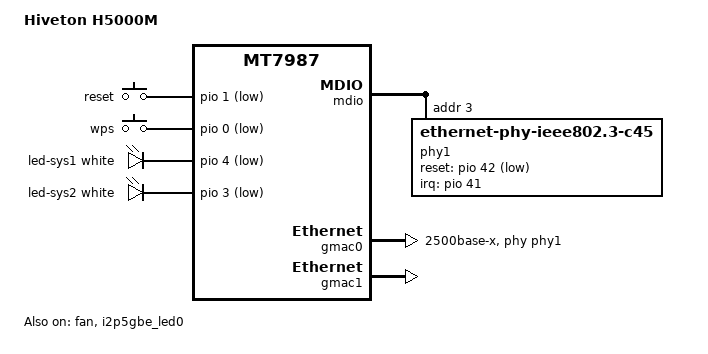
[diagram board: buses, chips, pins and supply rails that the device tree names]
// SPDX-License-Identifier: (GPL-2.0 OR MIT)
/*
 * Copyright (C) 2025 MediaTek Inc.
 * Author: Sam.Shih <sam.shih@mediatek.com>
 */

/dts-v1/;
#include "mt7987a.dtsi"
#include <dt-bindings/input/input.h>
#include "mt7987-emmc.dtsi"

/* MT7987A RFB DTS for DT overlay-based device tree */
/ {
	model = "Hiveton H5000M";
	compatible = "hiveton,h5000m", "mediatek,mt7987";

	chosen {
		bootargs = "console=ttyS0,115200n1 loglevel=8  \
                            earlycon=uart8250,mmio32,0x11000000 \
                            pci=pcie_bus_perf \
			    root=PARTLABEL=rootfs rootwait \
			    rootfstype=squashfs,f2fs";
	};

	gpio-keys {
		compatible = "gpio-keys";

		reset {
			label = "reset";
			linux,code = <KEY_RESTART>;
			gpios = <&pio 1 GPIO_ACTIVE_LOW>;
			debounce-interval = <10>;
		};

		wps {
			label = "wps";
			linux,code = <KEY_WPS_BUTTON>;
			gpios = <&pio 0 GPIO_ACTIVE_LOW>;
			debounce-interval = <10>;
		};
	};

	leds {
		compatible = "gpio-leds";

		led-sys1 {
			gpios = <&pio 4 GPIO_ACTIVE_LOW>;
			color = <LED_COLOR_ID_WHITE>;
			function = LED_FUNCTION_WLAN;
			function-enumerator = <1>;
		};

		led-sys2 {
			gpios = <&pio 3 GPIO_ACTIVE_LOW>;
			color = <LED_COLOR_ID_WHITE>;
			function = LED_FUNCTION_WLAN;
			function-enumerator = <0>;
		};
	};
};

&pcie0 {
	wifi-reset-gpios = <&pio 38 GPIO_ACTIVE_HIGH>;
	wifi-reset-msleep = <1000>;
};

&fan {
	pinctrl-names = "default";
	pinctrl-0 = <&pwm_fan_pins>;
	compatible = "pwm-fan";
	#cooling-cells = <2>;
	cooling-levels = <0 10 20 30 40 50 60 70 80 90 100 110 120 130 140 150 160 170 180 190 200 210 220 240 255>;
	pwms = <&pwm 1 50000 0>;
	status = "okay";
};

&mdio {
	phy1: phy@1 {
		compatible = "ethernet-phy-ieee802.3-c45";
		reg = <3>;
		reset-assert-us = <100000>;
		reset-deassert-us = <100000>;
		reset-gpios = <&pio 42 GPIO_ACTIVE_LOW>;
		interrupts = <41 IRQ_TYPE_LEVEL_LOW>;
		interrupt-parent = <&pio>;
		realtek,aldps-enable;
	};
};

&gmac0 {
	phy-mode = "2500base-x";
	phy-handle = <&phy1>;
	status = "okay";
};

&gmac1 {
	status = "okay";
};

&i2p5gbe_led0 {
	status = "okay";
};
